# max32570 register map
Vendor: Maxim-Integrated; Series: ARMCM4; File version: 1.0
CPU: CM4 r2p1, little endian, MPU, FPU, 3 interrupt priority bits
Registers are 32-bit, read-write, reset 0x0 unless marked. A register's access mark holds for its fields unless they carry their own. Offsets are from the block's base; [hi:lo] are bit positions; {n}, {i} and the like mark numbered series.

## HA — Hardware Accelerator
Base 0x40036000
0x00 IP ro — Q30E Instruction Pointer.
0x04 SP ro — Q30E Stack Pointer.
0x08 DP0 ro — Q30E Data Pointer 0.
0x0C DP1 ro — Q30E Data Pointer 1.
0x10 BP ro — Q30E Frame Pointer Base.
0x14 OFFS ro — Q30E Frame Pointer Offset.
0x18 LC0 ro — Q30E Loop Counter 0.
0x1C LC1 ro — Q30E Loop Counter 1.
{0x20+4i} A{i} ro (i=0..3) — Q30E Accumulator {i}.
0x30 WDCN ro — Q30E Watchdog Control.
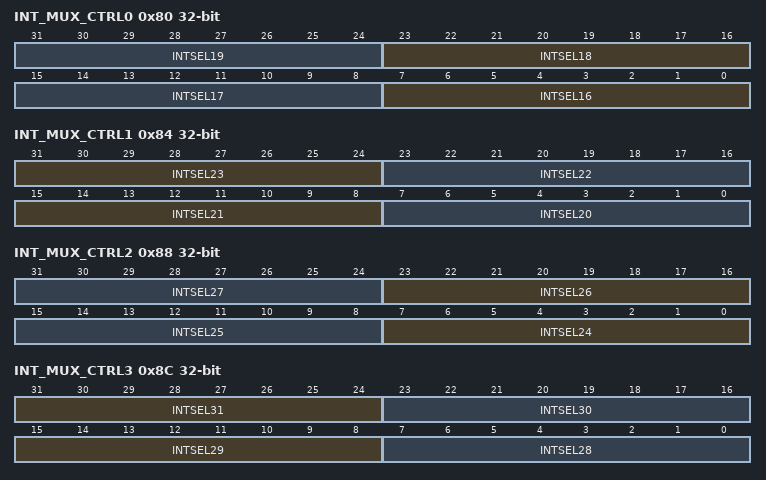
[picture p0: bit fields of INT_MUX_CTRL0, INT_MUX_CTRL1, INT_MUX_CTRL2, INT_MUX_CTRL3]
0x80 INT_MUX_CTRL0 — Interrupt Mux Control 0.
  [8n-121:8n-128] INTSEL{n} (n=16..19) — Interrupt Selection For {n}th Interrupt.
0x84 INT_MUX_CTRL1 — Interrupt Mux Control 1.
  [31:24] INTSEL23 — Interrupt Selection For 23rd Interrupt.
  [23:16] INTSEL22 — Interrupt Selection For 22nd Interrupt.
  [15:8] INTSEL21 — Interrupt Selection For 21st Interrupt.
  [7:0] INTSEL20 — Interrupt Selection For 20th Interrupt.
0x88 INT_MUX_CTRL2 — Interrupt Mux Control 2.
  [8n-185:8n-192] INTSEL{n} (n=24..27) — Interrupt Selection For {n}th Interrupt.
0x8C INT_MUX_CTRL3 — Interrupt Mux Control 3.
  [31:24] INTSEL31 — Interrupt Selection For 31st Interrupt.
  [23:16] INTSEL30 — Interrupt Selection For 30th Interrupt.
  [15:8] INTSEL29 — Interrupt Selection For 29th Interrupt.
  [7:0] INTSEL28 — Interrupt Selection For 28th Interrupt.
0x90 IP_ADDR — Configurable starting IP address for Q30E.
  [31:0] START_IP_ADDR — Starting IP address for Q30E
0x94 CTRL — Control Register.
  [0] EN — Enable SDMA.
    0=dis (Disable SDMA.); 1=en (Enable SDMA.)
0xA0 INT_IN_CTRL — Interrupt Input From CPU Control Register.
  [0] INTSET — Set Interrupt Flag.
    0=dis (Set interrupt Flag to 0.); 1=set (Set Interrupt Flag to 1.)
0xA4 INT_IN_FLAG — Interrupt Input From CPU Flag.
  [0] INTFLAG — Interrupt Flag.
    0=No Effect; 1=clear (INT_IN_FLAG =0)
0xA8 INT_IN_IE — Interrupt Input From CPU Enable.
  [0] INT_IN_EN — Interrupt Enable.
0xB0 IRQ_FLAG — Interrupt Output To CPU Flag.
  [0] IRQ_FLAG — Interrupt Flag.
0xB4 IRQ_IE — Interrupt Output To CPU Control Register.
  [0] IRQ_EN — Interrupt Enable.

## HTMR — High Speed Timer Module.
Base 0x4001B000
Same registers: HTMR1 0x4001C000
0x00 SEC reset not defined — HTimer Long-Interval Counter. This register contains the 32 most significant bits of the counter.
  [31:0] RTS — HTimer Long Interval Counter.
0x04 SSEC reset not defined — HTimer Short Interval Counter. This counter ticks every t_htclk (16.48uS). HTIMER_SEC is incremented when this register rolls over from 0xFF to 0x00.
  [7:0] RTSS — HTimer Short Interval Counter.
0x08 RAS reset not defined — Long Interval Alarm.
  [19:0] RAS — HTimer Long Interval Alarm. An Alarm is triggered when this value matches HTIMER_SEC[19:0]
0x0C RSSA reset not defined — HTimer Short Interval Alarm. This register contains the reload value for the short interval alarm, HTIMER_CTRL.alarm_ss_fl is raised on rollover.
  [31:0] RSSA — This register contains the reload value for the short interval alarm.
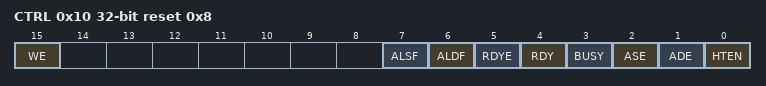
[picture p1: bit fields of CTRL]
0x10 CTRL reset 0x8 (reset mask 0xFFFFFF38) — HTimer Control Register.
  [15] WE — Write Enable. This register bit serves as a protection mechanism against unintentional writes to critical HTimer bits.
    0=dis (Not active.); 1=en
  [7] ALSF ro — Short Interval Alarm Interrupt Flag. This alarm is qualified as wake-up source to the processor.
    0=inactive (Not active.); 1=Pending (Active.)
  [6] ALDF ro — Long Interval Alarm Interrupt Flag. This alarm is qualified as wake-up source to the processor.
    0=inactive (Not active.); 1=pending (Active.)
  [5] RDYE — HTimer Ready Interrupt Enable.
    0=dis (Disable.); 1=en (Enable.)
  [4] RDY — HTimer Ready. This bit is set to 1 by hardware when the HTimer count registers update. It can be cleared to 0 by software at any time. It will also be cleared to 0 by hardware just prior to an update of the HTimer count register.
    0=busy (Register has not updated.); 1=ready
  [3] BUSY ro — HTimer Busy. This bit is set to 1 by hardware when changes to HTimer registers required a synchronized version of the register to be in place. This bit is automatically cleared by hardware.
    0=idle; 1=busy
  [2] ASE — Short Interval Alarm Interrupt Enable. Change to this bit is effective only after BUSY is cleared from 1 to 0.
    0=dis (Disable.); 1=en (Enable.)
  [1] ADE — Long Interval Alarm Interrupt Enable. Change to this bit is effective only after BUSY is cleared from 1 to 0.
    0=dis (Disable.); 1=en (Enable.)
  [0] HTEN — HTimer Enable. This bit enables the Real Time Clock. This bit can only be written when WE=1 and BUSY =0. Change to this bit is effective only after BUSY is cleared from 1 to 0.
    0=dis (Disable.); 1=en (Enable.)
